# STM32H7P5xx register map
File version: 1.0
Registers are 32-bit, read-write, reset 0x0 unless marked. A register's access mark holds for its fields unless they carry their own. Offsets are from the block's base; [hi:lo] are bit positions; 'fields as' and 'values as' point back to an identical list.

## XSPI1 — Extended-SPI interface (XSPI)
Base 0x52005000
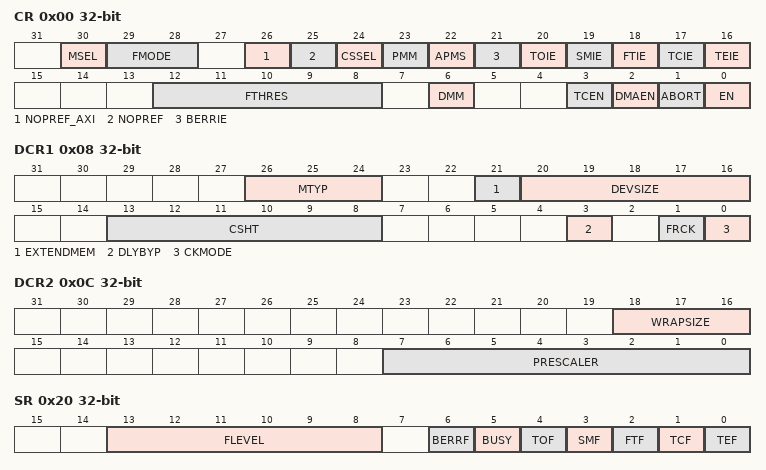
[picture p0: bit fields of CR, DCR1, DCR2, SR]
0x00 CR — XSPI control register
  [30] MSEL — External memory select
  [29:28] FMODE — Functional mode
  [26] NOPREF_AXI — No prefetch for signaled AXI transactions
  [25] NOPREF — No prefetch data
  [24] CSSEL — Chip-select selection
  [23] PMM — Polling match mode
  [22] APMS — Automatic status-polling mode stop
  [21] BERRIE — Bus error interrupt enable
  [20] TOIE — Timeout interrupt enable
  [19] SMIE — Status-match interrupt enable
  [18] FTIE — FIFO threshold interrupt enable
  [17] TCIE — Transfer complete interrupt enable
  [16] TEIE — Transfer error interrupt enable
  [12:8] FTHRES — FIFO threshold level
  [6] DMM — Dual-memory configuration
  [3] TCEN — Timeout counter enable
  [2] DMAEN — DMA enable
  [1] ABORT — Abort request
  [0] EN — Enable
0x08 DCR1 — XSPI device configuration register 1
  [26:24] MTYP — Memory type
  [21] EXTENDMEM — Extended memory support
  [20:16] DEVSIZE — Device size
  [13:8] CSHT — Chip-select high time
  [3] DLYBYP — Delay block bypass
  [1] FRCK — Free running clock
  [0] CKMODE — Clock mode 0
0x0C DCR2 — XSPI device configuration register 2
  [18:16] WRAPSIZE
  [7:0] PRESCALER — Clock prescaler
0x10 DCR3 — XSPI device configuration register 3
  [20:16] CSBOUND — NCS boundary
0x14 DCR4 — XSPI device configuration register 4
  [31:0] REFRESH — Refresh rate
0x20 SR ro — XSPI status register
  [13:8] FLEVEL — FIFO level
  [6] BERRF — Bus error flag
  [5] BUSY
  [4] TOF — Timeout flag
  [3] SMF — Status match flag
  [2] FTF — FIFO threshold flag
  [1] TCF — Transfer complete flag
  [0] TEF — Transfer error flag
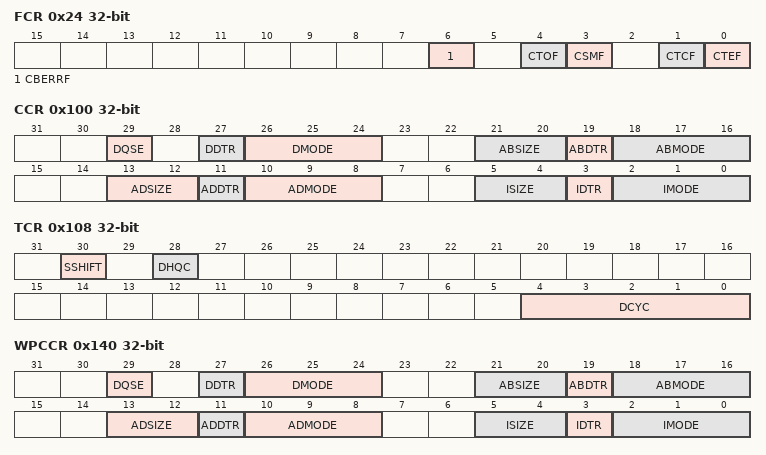
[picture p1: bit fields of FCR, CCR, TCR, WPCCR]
0x24 FCR — XSPI flag clear register
  [6] CBERRF — Clear bus error flag
  [4] CTOF — Clear timeout flag
  [3] CSMF — Clear status match flag
  [1] CTCF — Clear transfer complete flag
  [0] CTEF — Clear transfer error flag
0x40 DLR — XSPI data length register
  [31:0] DL — Data length
0x48 AR — XSPI address register
  [31:0] ADDRESS
0x50 DR — XSPI data register
  [31:0] DATA
0x80 PSMKR — XSPI polling status mask register
  [31:0] MASK — Status mask
0x88 PSMAR — XSPI polling status match register
  [31:0] MATCH — Status match
0x90 PIR — XSPI polling interval register
  [15:0] INTERVAL — Polling interval
0x100 CCR — XSPI communication configuration register
  [29] DQSE — DQS enable
  [27] DDTR — Data double transfer rate
  [26:24] DMODE — Data mode
  [21:20] ABSIZE — Alternate-byte size
  [19] ABDTR — Alternate- byte double transfer rate
  [18:16] ABMODE — Alternate-byte mode
  [13:12] ADSIZE — Address size
  [11] ADDTR — Address double transfer rate
  [10:8] ADMODE — Address mode
  [5:4] ISIZE — Instruction size
  [3] IDTR — Instruction double transfer rate
  [2:0] IMODE — Instruction mode
0x108 TCR — XSPI timing configuration register
  [30] SSHIFT — Sample shift
  [28] DHQC — Delay hold quarter cycle
  [4:0] DCYC — Number of dummy cycles
0x110 IR — XSPI instruction register
  [31:0] INSTRUCTION
0x120 ABR — XSPI alternate bytes register
  [31:0] ALTERNATE — Alternate bytes
0x130 LPTR — XSPI low-power timeout register
  [15:0] TIMEOUT — Timeout period
0x140 WPCCR — XSPI wrap communication configuration register
  [29] DQSE — DQS enable
  [27] DDTR — Data double transfer rate
  [26:24] DMODE — Data mode
  [21:20] ABSIZE — Alternate-byte size
  [19] ABDTR — Alternate-byte double transfer rate
  [18:16] ABMODE — Alternate-byte mode
  [13:12] ADSIZE — Address size
  [11] ADDTR — Address double transfer rate
  [10:8] ADMODE — Address mode
  [5:4] ISIZE — Instruction size
  [3] IDTR — Instruction double transfer rate
  [2:0] IMODE — Instruction mode
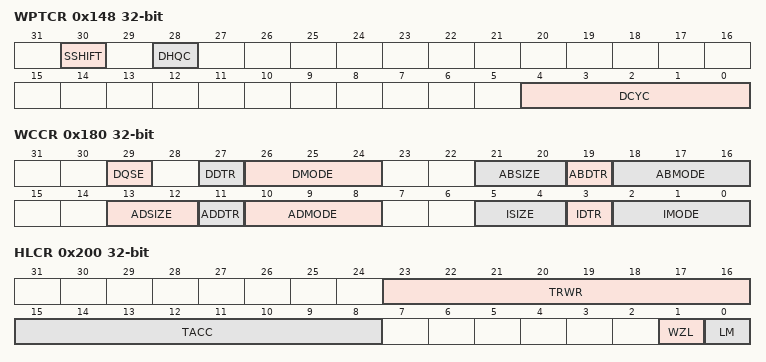
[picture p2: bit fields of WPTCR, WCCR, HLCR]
0x148 WPTCR — XSPI wrap timing configuration register
  fields as TCR
0x150 WPIR — XSPI wrap instruction register
  [31:0] INSTRUCTION
0x160 WPABR — XSPI wrap alternate bytes register
  [31:0] ALTERNATE — Alternate bytes
0x180 WCCR — XSPI write communication configuration register
  [29] DQSE — DQS enable
  [27] DDTR — data double transfer rate
  [26:24] DMODE — Data mode
  [21:20] ABSIZE — Alternate-byte size
  [19] ABDTR — Alternate bytes double transfer rate
  [18:16] ABMODE — Alternate-byte mode
  [13:12] ADSIZE — Address size
  [11] ADDTR — Address double transfer rate
  [10:8] ADMODE — Address mode
  [5:4] ISIZE — Instruction size
  [3] IDTR — Instruction double transfer rate
  [2:0] IMODE — Instruction mode
0x188 WTCR — XSPI write timing configuration register
  [4:0] DCYC — Number of dummy cycles
0x190 WIR — XSPI write instruction register
  [31:0] INSTRUCTION
0x1A0 WABR — XSPI write alternate bytes register
  [31:0] ALTERNATE — Alternate bytes
0x200 HLCR — XSPI HyperBus latency configuration register
  [23:16] TRWR — Read-write minimum recovery time
  [15:8] TACC — Access time
  [1] WZL — Write zero latency
  [0] LM — Latency mode
